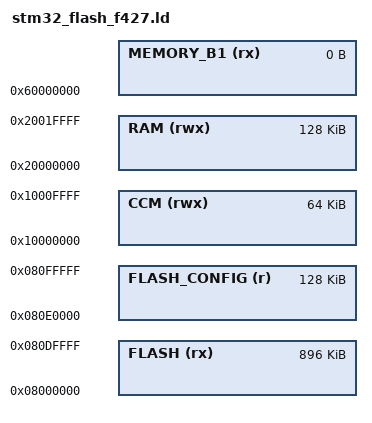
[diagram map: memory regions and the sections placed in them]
/*
*****************************************************************************
**
**  File        : stm32_flash.ld
**
**  Abstract    : Linker script for STM32F427 Device with
**                2048 KByte FLASH, 192KByte RAM
**
**                Set heap size, stack size and stack location according
**                to application requirements.
**
**                Set memory bank area and size if external memory is used.
**
**  Target      : STMicroelectronics STM32
**
**  Environment : Atollic TrueSTUDIO(R)
**
**  Distribution: The file is distributed “as is,” without any warranty
**                of any kind.
**
**  (c)Copyright Atollic AB.
**  You may use this file as-is or modify it according to the needs of your
**  project. Distribution of this file (unmodified or modified) is not
**  permitted. Atollic AB permit registered Atollic TrueSTUDIO(R) users the
**  rights to distribute the assembled, compiled & linked contents of this
**  file as part of an application binary file, provided that it is built
**  using the Atollic TrueSTUDIO(R) toolchain.
**
*****************************************************************************
*/

/* Entry Point */
ENTRY(Reset_Handler)

/*
0x08000000 to 0x08100000 1024K full flash,
0x08000000 to 0x080DFFFF 896K firmware,
0x080E0000 to 0x08100000 128K config,       // FLASH_Sector_11
*/

/* Specify the memory areas */
MEMORY
{
    FLASH (rx)        : ORIGIN = 0x08000000, LENGTH = 896K
    FLASH_CONFIG (r)  : ORIGIN = 0x080E0000, LENGTH = 128K

    RAM (rwx)         : ORIGIN = 0x20000000, LENGTH = 128K
    CCM (rwx)         : ORIGIN = 0x10000000, LENGTH = 64K
    MEMORY_B1 (rx)    : ORIGIN = 0x60000000, LENGTH = 0K
}

REGION_ALIAS("STACKRAM", CCM)

INCLUDE "stm32_flash.ld"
